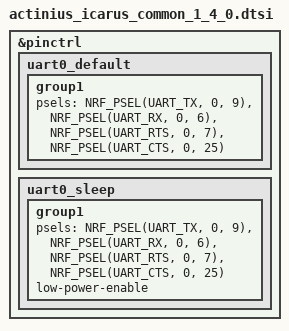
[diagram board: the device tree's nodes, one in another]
/*
 * Copyright (c) 2022 Actinius
 *
 * SPDX-License-Identifier: Apache-2.0
 */

&pinctrl {
	uart0_default: uart0_default {
		group1 {
			psels = <NRF_PSEL(UART_TX, 0, 9)>,
				<NRF_PSEL(UART_RX, 0, 6)>,
				<NRF_PSEL(UART_RTS, 0, 7)>,
				<NRF_PSEL(UART_CTS, 0, 25)>;
		};
	};

	uart0_sleep: uart0_sleep {
		group1 {
			psels = <NRF_PSEL(UART_TX, 0, 9)>,
				<NRF_PSEL(UART_RX, 0, 6)>,
				<NRF_PSEL(UART_RTS, 0, 7)>,
				<NRF_PSEL(UART_CTS, 0, 25)>;
			low-power-enable;
		};
	};
};
